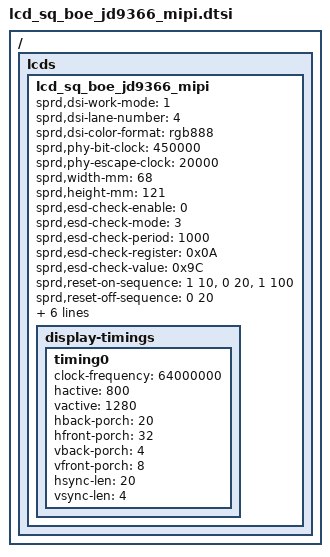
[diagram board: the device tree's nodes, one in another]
/ { lcds {
	lcd_sq_boe_jd9366_mipi: lcd_sq_boe_jd9366_mipi {

		sprd,dsi-work-mode = <1>;
		sprd,dsi-lane-number = <4>;
		sprd,dsi-color-format = "rgb888";

		sprd,phy-bit-clock = <450000>;
		sprd,phy-escape-clock = <20000>;

		sprd,width-mm = <68>;
		sprd,height-mm = <121>;

		sprd,esd-check-enable = <0>;
		sprd,esd-check-mode = <3>;
		sprd,esd-check-period = <1000>;
		sprd,esd-check-register = <0x0A>;
		sprd,esd-check-value = <0x9C>;

		sprd,reset-on-sequence = <1 10>, <0 20>, <1 100>;
		sprd,reset-off-sequence = <0 20>;

		sprd,initial-command = [
		
//--- PASSWORD  ----//
23  00  00  02 E1 93 
23  00  00  02 E2 65 
23  00  00  02 E3 F8 


//Page0
23  00  00  02 E0 00 
//--- Sequence Ctrl  ----//
23  00  00  02 70 02 	//DC0 DC1
23  00  00  02 71 23 	//DC2 DC3
23  00  00  02 72 06 	//DC7
23  00  00  02 80 03 
23  00  00  02 E6 02 
23  00  00  02 E7 02 
//--- Page1  ----//
23  00  00  02 E0 01 

//Set VCOM
23  00  00  02 00 00 
23  00  00  02 01 A0 
//Set VCOM_Reverse
23  00  00  02 03 00 
23  00  00  02 04 A0 

//Set Gamma Power  VGMP VGMN VGSP VGSN
23  00  00  02 17 00 
23  00  00  02 18 B1 
23  00  00  02 19 01 //00
23  00  00  02 1A 00 
23  00  00  02 1B B1   //VGMN=0
23  00  00  02 1C 01 //00
                
//Set Gate Power
23  00  00  02 1F 3E 
23  00  00  02 20 28 //2D	
23  00  00  02 21 28 //2D
23  00  00  02 22 0E 

//SETPANEL
23  00  00  02 37 19 	//SS=1 BGR=1

//SET RGBCYC
23  00  00  02 38 05 
23  00  00  02 39 08 
23  00  00  02 3A 12 
23  00  00  02 3C 78 
23  00  00  02 3E 80 
23  00  00  02 3F 80 


//Set TCON
23  00  00  02 40 06 	//RSO=800 RGB
23  00  00  02 41 A0 	//LN=640->1280 line
//23  00  00  02 4A 35  //BIST MODE

//--- power voltage  ----//
23  00  00  02 55 0F 	//DCDCM=0001  JD PWR_IC
23  00  00  02 56 01 
23  00  00  02 57 69 
23  00  00  02 58 0A 
23  00  00  02 59 0A 
23  00  00  02 5A 28 
23  00  00  02 5B 19 


//--- Gamma  ----//
23  00  00  02 5D 7C 
23  00  00  02 5E 5E 
23  00  00  02 5F 4E 
23  00  00  02 60 41 
23  00  00  02 61 3F 
23  00  00  02 62 31 
23  00  00  02 63 37 
23  00  00  02 64 23 
23  00  00  02 65 3E 
23  00  00  02 66 3F 
23  00  00  02 67 40 
23  00  00  02 68 5E 
23  00  00  02 69 4F 
23  00  00  02 6A 57 
23  00  00  02 6B 4B 
23  00  00  02 6C 49 
23  00  00  02 6D 2F 
23  00  00  02 6E 03 
23  00  00  02 6F 00 
23  00  00  02 70 7C 
23  00  00  02 71 5E 
23  00  00  02 72 4E 
23  00  00  02 73 41 
23  00  00  02 74 3F 
23  00  00  02 75 31 
23  00  00  02 76 37 
23  00  00  02 77 23 
23  00  00  02 78 3E 
23  00  00  02 79 3F 
23  00  00  02 7A 40 
23  00  00  02 7B 5E 
23  00  00  02 7C 4F 
23  00  00  02 7D 57 
23  00  00  02 7E 4B 
23  00  00  02 7F 49 
23  00  00  02 80 2F 
23  00  00  02 81 03 
23  00  00  02 82 00 


//Page2  for GIP
23  00  00  02 E0 02 

//GIP_L Pin mapping
23  00  00  02 00 47 
23  00  00  02 01 47   
23  00  00  02 02 45 
23  00  00  02 03 45 
23  00  00  02 04 4B 
23  00  00  02 05 4B 
23  00  00  02 06 49 
23  00  00  02 07 49 
23  00  00  02 08 41 
23  00  00  02 09 1F 
23  00  00  02 0A 1F 
23  00  00  02 0B 1F 
23  00  00  02 0C 1F 
23  00  00  02 0D 1F 
23  00  00  02 0E 1F 
23  00  00  02 0F 43 
23  00  00  02 10 1F 
23  00  00  02 11 1F 
23  00  00  02 12 1F 
23  00  00  02 13 1F 
23  00  00  02 14 1F 
23  00  00  02 15 1F 

//GIP_R Pin mapping
23  00  00  02 16 46 
23  00  00  02 17 46 
23  00  00  02 18 44 
23  00  00  02 19 44 
23  00  00  02 1A 4A 
23  00  00  02 1B 4A 
23  00  00  02 1C 48 
23  00  00  02 1D 48 
23  00  00  02 1E 40 
23  00  00  02 1F 1F 
23  00  00  02 20 1F 
23  00  00  02 21 1F 
23  00  00  02 22 1F 
23  00  00  02 23 1F 
23  00  00  02 24 1F 
23  00  00  02 25 42 
23  00  00  02 26 1F 
23  00  00  02 27 1F 
23  00  00  02 28 1F 
23  00  00  02 29 1F 
23  00  00  02 2A 1F 
23  00  00  02 2B 1F 

//GIP Timing


23  00  00  02 58 40  
			23  00  00  02 59 00  
			23  00  00  02 5A 00  
			23  00  00  02 5B 30  
			23  00  00  02 5C 03  
			23  00  00  02 5D 30  
			23  00  00  02 5E 01  
			23  00  00  02 5F 02  
			23  00  00  02 60 00  
			23  00  00  02 61 01  
			23  00  00  02 62 02  
			23  00  00  02 63 03  
			23  00  00  02 64 6B  
			23  00  00  02 65 00  
			23  00  00  02 66 00  
			23  00  00  02 67 73  
			23  00  00  02 68 05  
			23  00  00  02 69 06  
			23  00  00  02 6A 6B 
			23  00  00  02 6B 08  
			23  00  00  02 6C 00  
			23  00  00  02 6D 04  
			23  00  00  02 6E 04  
			23  00  00  02 6F 88  
			23  00  00  02 70 00  
			23  00  00  02 71 00  
			23  00  00  02 72 06  
			23  00  00  02 73 7B  
			23  00  00  02 74 00  
			23  00  00  02 75 07  
			23  00  00  02 76 00  
			23  00  00  02 77 5D  
			23  00  00  02 78 17  
			23  00  00  02 79 1F  
			23  00  00  02 7A 00  
			23  00  00  02 7B 00  
			23  00  00  02 7C 00  
			23  00  00  02 7D 03  
			23  00  00  02 7E 7B  
//Page1
23  00  00  02 E0 01 
23  00  00  02 0E 00 	//LEDON
//23  00  00  02 0E 01 	//LEDON output VCSW2

//Page3
23  00  00  02 E0 03 
23  00  00  02 98 3F 	//From 2E to 2F  LED_VOL

23  00  00  02 E0 04 
23  00  00  02 2B 2B 
23  00  00  02 2E 44 
23  00  00  02 09 10 
23  00  00  02 2D 03 

//Page0
23  00  00  02 E0 00 
			13 78 00 01 11
			13 64 00 01 29
			];
		sprd,sleep-in-command = [
			13 0A 00 01 28
			13 78 00 01 10
			];
		sprd,sleep-out-command = [
			13 78 00 01 11
			13 64 00 01 29
			];

		display-timings {
			timing0 {
			clock-frequency = <64000000>;
			hactive = <800>;
			vactive = <1280>;
			hback-porch = <20>;
			hfront-porch = <32>;
			vback-porch = <4>;
			vfront-porch = <8>;
			hsync-len = <20>;
			vsync-len = <4>;
			};
		};
	};
};};

